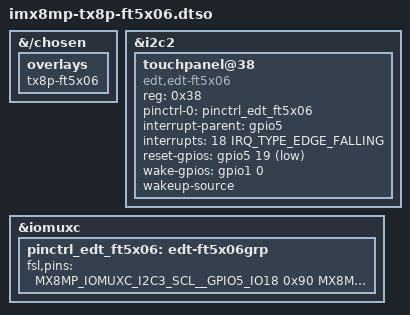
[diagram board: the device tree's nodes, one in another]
// SPDX-License-Identifier: (GPL-2.0 OR MIT)
/*
 * Copyright 2022 Lothar Waßmann <LW@KARO-electronics.de>
 *
 */

/dts-v1/;
/plugin/;

#include <dt-bindings/gpio/gpio.h>
#include <dt-bindings/interrupt-controller/irq.h>
#include "imx8mp-pinfunc.h"

&{/chosen} {
	overlays {
		tx8p-ft5x06;
	};
};

&i2c2 {
	status = "okay";

	touchpanel@38 {
		compatible = "edt,edt-ft5x06";
		reg = <0x38>;
		pinctrl-names = "default";
		pinctrl-0 = <&pinctrl_edt_ft5x06>;
		interrupt-parent = <&gpio5>;
		interrupts = <18 IRQ_TYPE_EDGE_FALLING>;
		reset-gpios = <&gpio5 19 GPIO_ACTIVE_LOW>;
		wake-gpios = <&gpio1 0 GPIO_ACTIVE_HIGH>;
		wakeup-source;
	};
};

&iomuxc {
	pinctrl_edt_ft5x06: edt-ft5x06grp {
		fsl,pins = <
			MX8MP_IOMUXC_I2C3_SCL__GPIO5_IO18		0x90 /* Interrupt */
			MX8MP_IOMUXC_I2C3_SDA__GPIO5_IO19		0x1b0b0 /* Reset */
			MX8MP_IOMUXC_GPIO1_IO00__GPIO1_IO00		0x1b0b0 /* Wake */
		>;
	};
};
